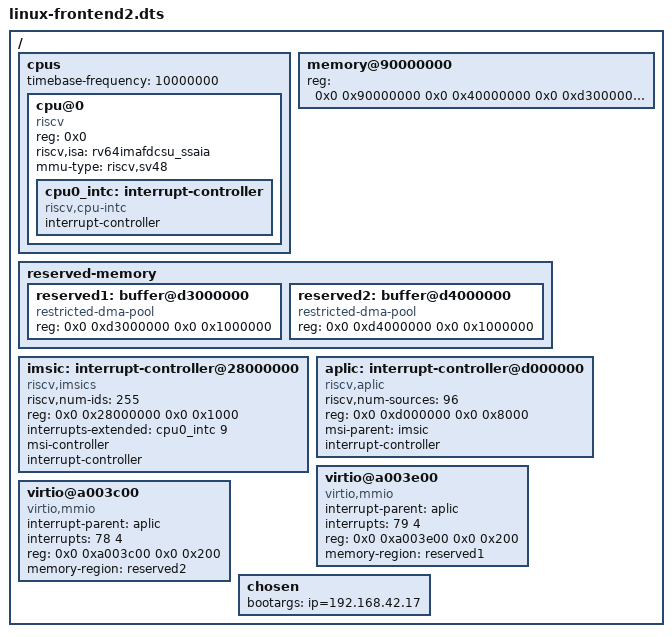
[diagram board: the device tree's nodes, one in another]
/dts-v1/;

/ {
	#address-cells = <0x2>;
	#size-cells = <0x2>;

	cpus {
		#address-cells = <0x1>;
		#size-cells = <0x0>;
		timebase-frequency = <10000000>;

		cpu@0 {
			device_type = "cpu";
			reg = <0x0>;
			status = "okay";
			compatible = "riscv";
			riscv,isa = "rv64imafdcsu_ssaia";
			mmu-type = "riscv,sv48";

			cpu0_intc: interrupt-controller {
				#interrupt-cells = <0x1>;
				interrupt-controller;
				compatible = "riscv,cpu-intc";
			};
		};
	};

	memory@90000000 {
		device_type = "memory";
		reg = <0x0 0x90000000 0x0 0x40000000
			   0x0 0xd3000000 0x0 0x02000000>;
	};
	
	reserved-memory {
		#address-cells = <0x2>;
		#size-cells = <0x2>;
		ranges;
	
		reserved1: buffer@d3000000 {
		    compatible = "restricted-dma-pool";			
		    reg = <0x0 0xd3000000 0x0 0x1000000>;
		};

		reserved2: buffer@d4000000 {
		    compatible = "restricted-dma-pool";			
		    reg = <0x0 0xd4000000 0x0 0x1000000>;
		};
    };

	imsic: interrupt-controller@28000000 {
		riscv,num-ids = <255>;
		reg = <0x0 0x28000000 0x0 0x1000>;
		interrupts-extended = <
			&cpu0_intc 9
		>;
		msi-controller;
		interrupt-controller;
		compatible = "riscv,imsics";
		#interrupt-cells = <0x0>;
	};

	aplic: interrupt-controller@d000000 {
		riscv,num-sources = <96>;
		reg = <0x0 0xd000000 0x0 0x8000>;
		msi-parent = <&imsic>;
		interrupt-controller;
		compatible = "riscv,aplic";
		#interrupt-cells = <0x2>;
	};

	virtio@a003e00 {
		interrupt-parent = <&aplic>;
		interrupts = <79 4>;
		reg = <0x0 0xa003e00 0x0 0x200>;
		compatible = "virtio,mmio";
		memory-region = <&reserved1>;	
	};

	virtio@a003c00 {
		interrupt-parent = <&aplic>;
		interrupts = <78 4>;
		reg = <0x0 0xa003c00 0x0 0x200>;
		compatible = "virtio,mmio";
		memory-region = <&reserved2>;	
	};

	chosen {
		bootargs = "ip=192.168.42.17";
	};
};
